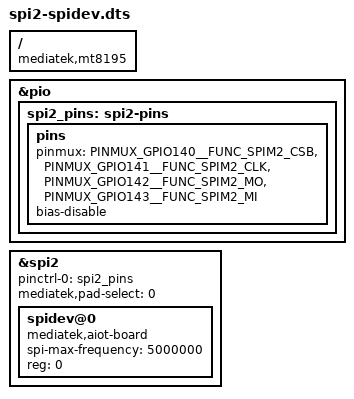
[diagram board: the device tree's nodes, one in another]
// SPDX-License-Identifier: GPL-2.0
/*
 * Copyright (c) 2023 Radxa Limited
 *
 */

#include <dt-bindings/pinctrl/mt8195-pinfunc.h>

/dts-v1/;
/plugin/;

/ {
	compatible = "mediatek,mt8195";

	fragment@0 {
		target = <&pio>;
		__overlay__ {
			spi2_pins: spi2-pins {
				pins {
					pinmux = <PINMUX_GPIO140__FUNC_SPIM2_CSB>,
						 <PINMUX_GPIO141__FUNC_SPIM2_CLK>,
						 <PINMUX_GPIO142__FUNC_SPIM2_MO>,
						 <PINMUX_GPIO143__FUNC_SPIM2_MI>;
					bias-disable;
				};
			};
		};
	};

	fragment@1 {
		target = <&spi2>;
		__overlay__ {
			pinctrl-0 = <&spi2_pins>;
			pinctrl-names = "default";
			mediatek,pad-select = <0>;
			#address-cells = <1>;
			#size-cells = <0>;
			status = "okay";

			spidev@0 {
				compatible = "mediatek,aiot-board";
				spi-max-frequency = <5000000>;
				reg = <0>;
			};
		};
	};
};
